# ecd5_target_db register map
Vendor: Texas Instruments
Peripheral module from a debugger description file (folder iva2_arp32).
Address unit: 16 bits
Registers are 32-bit, access per field, reset 0x0 unless marked. A register's access mark holds for its fields unless they carry their own. Offsets are as the file gives them; lines under a group give offsets from that group; [hi:lo] are bit positions; {n}, {i} and the like mark numbered series; 'fields as' and 'values as' point back to an identical list; <NAME> marks a mode.

## DSS (part 1 of 5) — ipxact12_to_ccs_generated
0x00 __ALL___PID ro — ECD5 PID
0x00 __ALL___SL2_BUF_ADDR_SLICEINFO — sliceInfo SL2 Buffer Base Address
  [21:0] ADDR rw — Base Address of sliceInfo in SL2 (128 bit aligned); bits[3:0] hardwired to 0
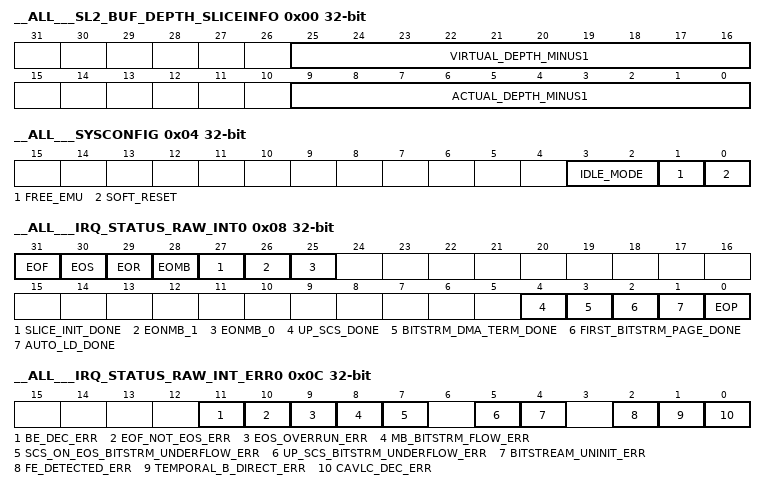
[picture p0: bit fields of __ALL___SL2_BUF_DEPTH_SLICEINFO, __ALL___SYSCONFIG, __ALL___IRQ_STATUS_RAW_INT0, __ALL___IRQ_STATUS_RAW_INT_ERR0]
0x00 __ALL___SL2_BUF_DEPTH_SLICEINFO — Buffer Control Parameters for sliceInfo Buffer Note : This register is used by the FE for handling the SL2BC to the BE and ROP as well as for describing the input sliceInfo buffer to FE.
  [25:16] VIRTUAL_DEPTH_MINUS1 rw — BC Virtual Depth
  [9:0] ACTUAL_DEPTH_MINUS1 rw — BC Actual Depth
0x04 __ALL___SYSCONFIG — SYSCONFIG
  [3:2] IDLE_MODE rw, [1] FREE_EMU rw, [0] SOFT_RESET rw
0x04 __ALL___SL2_BUF_ADDR_BITSTRM — Bitstream SL2 Buffer Base Address
  [21:0] ADDR rw — Base address of bit stream buffer in SL2 (128 bit aligned); bits[3:0] hardwired to 0
0x04 __ALL___SL2_BUF_START_PTR_SLICEINFO — Buffer Control Pointers for sliceInfo Buffer (to BE + ROP) Note : This register is used by the FE for handling the SL2BC to the BE and ROP as well as for describing the input sliceInfo buffer to FE.
  [9:0] START_PTR rw — BC Start Value for Write Pointer. Also used as the start value for reading the sliceInfo buffer by the FE.
0x08 __ALL___IRQ_STATUS_RAW_INT0 — Raw status of sources for interrupt INT0. Raw status is set even if the interrupt is not enabled; Write 1 to set the raw status (mostly for debug) The following is the behavior for read/write into each of the individual fields : Write 0: No action Write 1: Set event (for debug) Read 0: No event pending Read 1: Event pending
  [31] EOF rw — End of Frame Status.
  [30] EOS rw — End of Slice Status.
  [29] EOR rw — End of Row Status.
  [28] EOMB rw — End of Macroblock Status.
  [27] SLICE_INIT_DONE rw — Slice init done status
  [26] EONMB_1 rw — End of N Macroblock (i.e. counter 1 expired) Status.
  [25] EONMB_0 rw — End of N Macroblock (i.e. counter 0 expired) Status.
  [4] UP_SCS_DONE rw — Unit processing startcode search done. This bit is valid only in CAVLC decode.
  [3] BITSTRM_DMA_TERM_DONE rw — Bitstream DMA termination completed status. This bit is valid only in CAVLC decode.
  [2] FIRST_BITSTRM_PAGE_DONE rw — DMA of first page of bitstream fetch from DDR to SL2 completed in decode status. This bit is valid only in CAVLC decode.
  [1] AUTO_LD_DONE rw — Auto Load Done Status.
  [0] EOP rw — End of Pipe Status.
{0x8+4i} __ALL___SL2_BUF_ADDR_BIN{i} (i=0..3) — Bin Stream {i} SL2 Buffer base address
  [21:0] ADDR rw — Base Address of Bin stream {i} in SL2 (128 bit aligned); bits[3:0] hardwired to 0
0x08 __ALL___SL2_BUF_PTR_INC_SLICEINFO reset 0x1 — Buffer Control Pointer Increment Parameters for sliceInfo buffer (to BE + ROP) Note : This register is used by the FE for handling the SL2BC to the BE and ROP as well as for describing the input sliceInfo buffer to FE.
  [9:0] PTR_INC rw — BC Increment value for Write pointer. Also used as the increment value for the read pointer for reading sliceInfo buffer by FE.
0x0C __ALL___IRQ_STATUS_RAW_INT_ERR0 — Raw status of sources for interrupt INT_ERR0 Raw status is set even if the interrupt is not enabled; Write 1 to set the raw status (mostly for debug) The following is the behavior for read/write into each of the individual fields : Write 0: No action Write 1: Set event (for debug) Read 0: No event pending Read 1: Event pending
  [11] BE_DEC_ERR rw — BE Decoder Error. Tthe exact source of error is reflected in BE_STATUS.BE_CORE_ERR_STATUS
  [10] EOF_NOT_EOS_ERR rw — End of frame is not end of slice error. This bit is valid only in CAVLC decode. This error status bit is set if the corresponding error enable bit (BE_FUNC.CAVLC_CFG.EOF_NOT_EOS_ERROR_ENABLE) is set and the following condition is true : - End of slice is not detected in the CAVLC bitstream, but all MBs in the picture have been decoded.
  [9] EOS_OVERRUN_ERR rw — End of slice overrun error. This bit is valid only in CAVLC decode. This error status bit is set, if during MB decoding, bit pointer overruns the position of end of slice. Byte stream format : If the bit pointer overruns the start code of the next slice, this status bit is set. NALU or fragmented NALU format : If the bit counter reaches the programmed size (BITSTRMx_CTRL.SBC_NALU_CFG.SIZE) of NALU and slice data decode is not completed, this status bit is set
  [8] MB_BITSTRM_FLOW_ERR rw — During decode, underflow in bitstream during MB decode error. This bit is valid only in CAVLC decode or encode. This error status bit is set when the ECD5 reached the end of the provided bitstream during macroblock decode. During encode, overflow in bitstream during MB encode error. This error status bit is set when the ECD5 reached the end of the provided DDR buffer during macroblock encode.
  [7] SCS_ON_EOS_BITSTRM_UNDERFLOW_ERR rw — Underflow in bitstream during startcode search after EOS error. This bit is valid only in CAVLC decode. This error status bit is set when the ECD5 does not detect startcode even after decoding all the bitstream data provided, while doing a startcode search after EOS.
  [5] UP_SCS_BITSTRM_UNDERFLOW_ERR rw — Underflow in bitstream during startcode search unit processing This bit is valid only in CAVLC decode. This error status bit is set when the ECD5 does not detect startcode even after decoding all the bitstream data provided, while doing startcode search unit processing.
  [4] BITSTREAM_UNINIT_ERR rw — Bitstream descriptors were not programmed when bit stream DMA was initialized, error. This bit is valid only in CAVLC decode. This error status bit is set when bit-stream DMA is triggered (internally by the HW, or externally through SW programmation) but the bit-stream descriptors have not been programmed before this happens.
  [2] FE_DETECTED_ERR rw — BE error due to error detected in FE. This bit is valid only in CABAC decode , in both frame decoupled and non-frame-decoupled modes. This error status bit is set when the ECD5 detects an error in the BE, due to an error indication from the FE. The error indication from the FE is obtained as follows : - in frame decoupled mode, when the BE reaches an MB programmed as an error MB in BE_ERROR_MB_CFG - in non-frame decoupled mode, when the BE reaches an MB indicated as an error MB through internal signalling from the BE
  [1] TEMPORAL_B_DIRECT_ERR rw — Temporal B Direct Detected Error. This bit is valid only in CAVLC decode. This error status bit is set if Temporal B Direct decode is disabled (by setting BE_FUNC.CAVLC_CFG.TEMPORAL_B_DIRECT_ERROR_ENABLE to 1) and a Temporal B Direct MB is detected in the decoded (CAVLC) bit stream
  [0] CAVLC_DEC_ERR rw — CAVLC Decoder Error. This bit is valid only in CAVLC decode. Tthe exact source of error is reflected in BE_STAT.CAVLC_ERR_STATUS
0x0C __ALL___SL2_BUF_DEPTH_MB — Buffer Control Parameters for MB decoupling between FE and BE Note : Valid only in N MB decoupled mode
  [9:0] ACTUAL_DEPTH_MINUS1 rw — BC Actual Depth
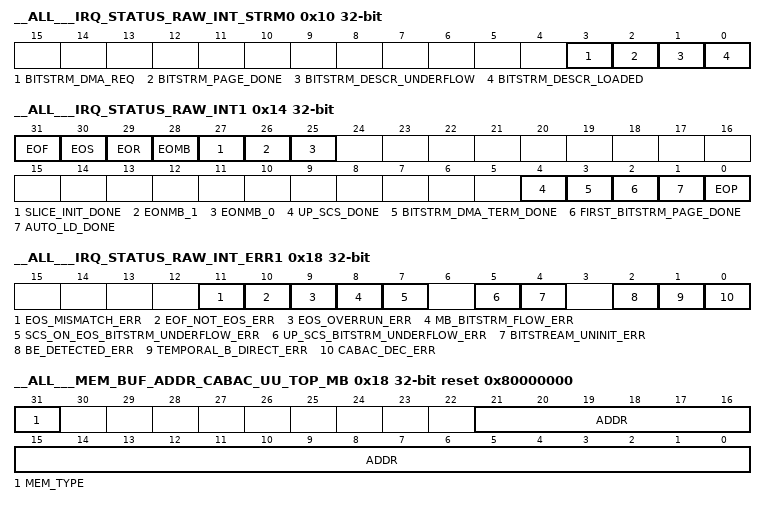
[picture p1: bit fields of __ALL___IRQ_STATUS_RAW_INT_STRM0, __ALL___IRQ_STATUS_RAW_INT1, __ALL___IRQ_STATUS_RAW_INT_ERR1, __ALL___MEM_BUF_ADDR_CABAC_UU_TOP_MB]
0x10 __ALL___IRQ_STATUS_RAW_INT_STRM0 — Raw status of sources for interrupt INT_STRM0 Raw status is set even if the interrupt is not enabled; Write 1 to set the raw status (mostly for debug) The following is the behavior for read/write into each of the individual fields : Write 0: No action Write 1: Set event (for debug) Read 0: No event pending Read 1: Event pending
  [3] BITSTRM_DMA_REQ rw — DMA request status. This bit is valid only in SW interactive mode of bitstream DMA - if "1" indicates that a request for DMA of 1 page of bitstream data is pending
  [2] BITSTRM_PAGE_DONE rw — Status bit indicating completion of - in decode, DMA of 1 page of bitstream fetch from DDR to SL2 - in encode, DMA of 1 page of bitstream write from SL2 to DDR
  [1] BITSTRM_DESCR_UNDERFLOW rw — DDR or SL2 bitstream data descriptor underflow status. In regular mode of bitstream DRM operation, this bit is set when contents of DDR_BITSTRM_INC_VALID_PAGES_SHADOW in the BITSTRM0_CTRL register set transitions to 0, and the corresponding non-shadow register - DDR_BITSTRM_INC_VALID_PAGES - has not yet been programmed with new value. In DMSP mode of bitstream DRM operation, this bit is set when contents of SL2_BITSTRM_INC_VALID_PAGES_SHADOW in the BITSTRM0_CTRL register set transitions to 0, and the corresponding non-shadow register - SL2_BITSTRM_INC_VALID_PAGES - has not yet been programmed with new value.
  [0] BITSTRM_DESCR_LOADED rw — DDR or SL2 bitstream data descriptor loaded status. In regular mode of bitstream DRM operation, this bit is set when contents of DDR_BITSTRM_INC_VALID_PAGES in the BITSTRM0_CTRL register set are copied into the corresponding shadow register, when the DDR_BITSTRM_INC_VALID_PAGES_SHADOW register contents transition to 0 Note that this bit is not set when the shadow registers are updated for the first time (i.e. when DDR_BITSTRM_INC_VALID_PAGES is written for the first time (and the corresponding shadow register is empty) In DMSP mode of bitstream DRM operation, this bit is set when contents of SL2_BITSTRM_INC_VALID_PAGES in the BITSTRM0_CTRL register set are copied into the corresponding shadow register, when the SL2_BITSTRM_INC_VALID_PAGES_SHADOW register contents transition to 0 Note that this bit is not set when the shadow registers are updated for the first time (i.e. when SL2_BITSTRM_INC_VALID_PAGES is written for the first time (and the corresponding shadow register is empty)
0x14 __ALL___IRQ_STATUS_RAW_INT1 — Raw status of sources for interrupt INT1; Raw status is set even if the interrupt is not enabled; Write 1 to set the raw status (mostly for debug) The following is the behavior for read/write into each of the individual fields : Write 0: No action Write 1: Set event (for debug) Read 0: No event pending Read 1: Event pending
  [31] EOF rw — End of Frame Status
  [30] EOS rw — End of Slice Status
  [29] EOR rw — End of Row Status
  [28] EOMB rw — End of Macroblock Status
  [27] SLICE_INIT_DONE rw — Slice init done status
  [26] EONMB_1 rw — End of N Macroblock (i.e. counter 1 expired) Status.
  [25] EONMB_0 rw — End of N Macroblock (i.e. counter 0 expired) Status.
  [4] UP_SCS_DONE rw — Unit processing startcode search done. This bit is valid only in CABAC decode.
  [3] BITSTRM_DMA_TERM_DONE rw — Bitstream DMA termination completed status. This bit is valid only in CABAC decode.
  [2] FIRST_BITSTRM_PAGE_DONE rw — DMA of first page of bitstream fetch from DDR to SL2 completed in decode status. This bit is valid only in CABAC decode.
  [1] AUTO_LD_DONE rw — Auto Load Done Status
  [0] EOP rw — End of Pipe Status
0x18 __ALL___IRQ_STATUS_RAW_INT_ERR1 — Raw status of sources for interrupt INT_ERR1 Raw status is set even if the interrupt is not enabled; Write 1 to set the raw status (mostly for debug) The following is the behavior for read/write into each of the individual fields : Write 0: No action Write 1: Set event (for debug) Read 0: No event pending Read 1: Event pending
  [11] EOS_MISMATCH_ERR rw — End of slice mismatch error. This bit is valid only in CABAC decode. This error status bit is set if the corresponding error enable bit (FE_FUNC.CABAC_CFG.EOS_MISMATCH_ERROR_ENABLE) is set and one of the following conditions is true : * There is no more data in the CABAC bitstream (more_rbsp_data() is false), but end of slice is not detected in the bitstream * End of slice is detected in the CABAC bitstream, but there is still more data to be decoded in the slice (more_rbsp_data() is true)
  [10] EOF_NOT_EOS_ERR rw — End of frame is not end of slice error. This bit is valid only in CABAC decode. This error status bit is set if the corresponding error enable bit (FE_FUNC.CABAC_CFG.EOF_NOT_EOS_ERROR_ENABLE) is set and if the following conditions is true : - End of slice is not detected in the CABAC bitstream, but all MBs in the picture have been decoded.
  [9] EOS_OVERRUN_ERR rw — End of slice overrun error. This bit is valid only in CABAC decode. This error status bit is set, if during MB decoding, bit pointer overruns the position of end of slice. Byte stream format : If the bit pointer overruns the start code of the next slice, this status bit is set. NALU or fragmented NALU format : If the bit counter reaches the programmed size (BITSTRMx_CTRL.SBC_NALU_CFG.SIZE) of NALU and slice data decode is not completed, this status bit is set
  [8] MB_BITSTRM_FLOW_ERR rw — During decode, underflow in bitstream during MB decode error. This bit is valid only in CABAC decode. This error status bit is set when the ECD5 reached the end of the provided bitstream during macroblock decode.
  [7] SCS_ON_EOS_BITSTRM_UNDERFLOW_ERR rw — Underflow in bitstream during startcode search after EOS error. This bit is valid only in CABAC decode. This error status bit is set when the ECD5 does not detect startcode even after decoding all the bitstream data provided, while doing a startcode search after EOS.
  [5] UP_SCS_BITSTRM_UNDERFLOW_ERR rw — Underflow in bitstream during startcode search unit processing This error status bit is set when the ECD5 does not detect startcode even after decoding all the bitstream data provided, while doing startcode search unit processing.
  [4] BITSTREAM_UNINIT_ERR rw — Bitstream descriptors were not programmed when bit stream DMA was initialized, error. This bit is valid only in CABAC decode. This error status bit is set when bit-stream DMA is triggered (internally by the HW, or externally through SW programmation) but the bit-stream descriptors have not been programmed before this happens.
  [2] BE_DETECTED_ERR rw — FE error due to error detected in BE. This bit is valid only in CABAC decode in non-frame decoupled mode, or in CAVLC decode. This error status bit is set when the ECD5 detects an error in the FE, due to an error indication from the BE through internal signalling.
  [1] TEMPORAL_B_DIRECT_ERR rw — Temporal B Direct Detected Error. This error status bit is set if Temporal B Direct decode is disabled (by setting FE_FUNC.CABAC_CFG.TEMPORAL_B_DIRECT_ERROR_ENABLE to 1) and a Temporal B Direct MB is detected in the decoded (CABAC) bit stream
  [0] CABAC_DEC_ERR rw — CABAC Decoder Error; the exact source of error is reflected in FE_STATUS.CABAC_ERR_STATUS
0x18 __ALL___MEM_BUF_ADDR_CABAC_UU_TOP_MB reset 0x80000000 — Upper Top MB Buffer Base Address for CABAC neighouring MB data in internal memory or SL2
  [31] MEM_TYPE rw — Specifies whether buffer is in SL2 or internal memory 0 : SL2, 1 : Internal memory
  [21:0] ADDR rw — Base Address for Upper MB Row, Top MB in the Pair If MEM_TYPE == 0, address in SL2 (128 bit aligned) specified; bits[3:0] hardwired to 0 If MEM_TYPE == 1, address in internal memory (128 bit aligned) specified;bits[3:0] hardwired to 0; bits [22:15] unused.
{0x18+8i} __ALL___SL2_BUF_DEPTH_BIN{i} (i=0..3) — Buffer Control Parameters for bin stream {i} Note : Valid only in N MB decoupled mode
  [15:0] ACTUAL_DEPTH_MINUS1 rw — BC Actual Depth
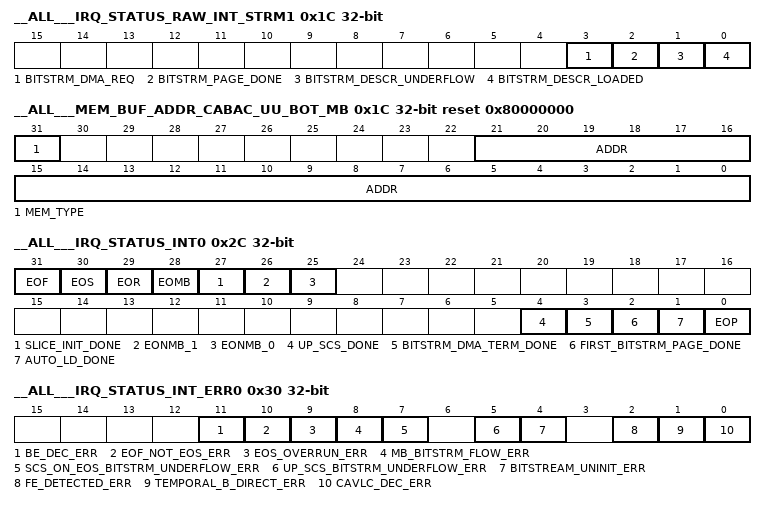
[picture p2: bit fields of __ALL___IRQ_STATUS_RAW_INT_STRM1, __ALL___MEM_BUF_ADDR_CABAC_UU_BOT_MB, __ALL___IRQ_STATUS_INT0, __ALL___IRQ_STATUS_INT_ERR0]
0x1C __ALL___IRQ_STATUS_RAW_INT_STRM1 — Raw status of sources for interrupt INT_STRM1 Raw status is set even if the interrupt is not enabled; Write 1 to set the raw status (mostly for debug) The following is the behavior for read/write into each of the individual fields : Write 0: No action Write 1: Set event (for debug) Read 0: No event pending Read 1: Event pending
  [3] BITSTRM_DMA_REQ rw — DMA request status. This bit is valid only in SW interactive mode of bitstream DMA - if "1" indicates that a request for DMA of 1 page of bitstream data is pending
  [2] BITSTRM_PAGE_DONE rw — Status bit indicating completion of - in decode, DMA of 1 page of bitstream fetch from DDR to SL2 - in encode, DMA of 1 page of bitstream write from SL2 to DDR
  [1] BITSTRM_DESCR_UNDERFLOW rw — DDR or SL2 bitstream data descriptor underflow status. In regular mode of bitstream DRM operation, this bit is set when contents of DDR_BITSTRM_INC_VALID_PAGES_SHADOW in the BITSTRM1_CTRL register set transitions to 0, and the corresponding non-shadow register - DDR_BITSTRM_INC_VALID_PAGES - has not yet been programmed with new value. In DMSP mode of bitstream DRM operation, this bit is set when contents of SL2_BITSTRM_INC_VALID_PAGES_SHADOW in the BITSTRM1_CTRL register set transitions to 0, and the corresponding non-shadow register - SL2_BITSTRM_INC_VALID_PAGES - has not yet been programmed with new value.
  [0] BITSTRM_DESCR_LOADED rw — DDR or SL2 bitstream data descriptor loaded status. In regular mode of bitstream DRM operation, this bit is set when contents of DDR_BITSTRM_INC_VALID_PAGES in the BITSTRM1_CTRL register set are copied into the corresponding shadow register, when the DDR_BITSTRM_INC_VALID_PAGES_SHADOW register contents transition to 0 Note that this bit is not set when the shadow registers are updated for the first time (i.e. when DDR_BITSTRM_INC_VALID_PAGES is written for the first time (and the corresponding shadow register is empty) In DMSP mode of bitstream DRM operation, this bit is set when contents of SL2_BITSTRM_INC_VALID_PAGES in the BITSTRM1_CTRL register set are copied into the corresponding shadow register, when the SL2_BITSTRM_INC_VALID_PAGES_SHADOW register contents transition to 0 Note that this bit is not set when the shadow registers are updated for the first time (i.e. when SL2_BITSTRM_INC_VALID_PAGES is written for the first time (and the corresponding shadow register is empty)
0x1C __ALL___MEM_BUF_ADDR_CABAC_UU_BOT_MB reset 0x80000000 — Upper Top MB Buffer Base Address for CABAC neighouring MB data in internal memory or SL2
  [31] MEM_TYPE rw — Specifies whether buffer is in SL2 or internal memory 0 : SL2, 1 : Internal memory
  [21:0] ADDR rw — Base Address for Upper MB Row, Bottom MB in the Pair If MEM_TYPE == 0, address in SL2 (128 bit aligned) specified; bits[3:0] hardwired to 0 If MEM_TYPE == 1, address in internal memory (128 bit aligned) specified;bits[3:0] hardwired to 0; bits [22:15] unused.
{0x1C+8i} __ALL___SL2_BUF_START_PTR_BIN{i} rw (i=0..3) — Buffer Control Pointers for bin stream {i} Note : Valid only in N MB decoupled mode
  [15:0] WRITE_START_PTR — BC Start Value for Write Pointer
0x2C __ALL___IRQ_STATUS_INT0 — Status of enabled sources for interrupt INT0. The individual status bits are not set, unless the source is enabled (by setting corresponding bit in IRQ_ENABLE_SET register) Write "1" to specific bit in this register to clear the status after interrupt has been serviced. Note : Writing "1" clears the "raw" status as well Note : Writing "1" generates internal EOI. The interrupt line is pulsed again, if any of the interrupt sources are still active (any of the status bits are "1") after the write of "1". The following is the behavior for read/write into each of the individual fields : Write 0: No action Write 1: Clear (raw) event - clears the corresponding bit in this register as well as the "raw" status bit in the IRQ_STATUS_RAW register Read 0: No enabled event pending Read 1: Event pending
  [31] EOF rw — End of Frame Status
  [30] EOS rw — End of Slice Status
  [29] EOR rw — End of Row Status
  [28] EOMB rw — End of Macroblock Status
  [27] SLICE_INIT_DONE rw — Slice init done status
  [26] EONMB_1 rw — End of N Macroblock (i.e. counter 1 expired) Status.
  [25] EONMB_0 rw — End of N Macroblock (i.e. counter 0 expired) Status.
  [4] UP_SCS_DONE rw — Unit processing startcode search done. This bit is valid only in CAVLC decode.
  [3] BITSTRM_DMA_TERM_DONE rw — Bitstream DMA termination completed status. This bit is valid only in CAVLC decode.
  [2] FIRST_BITSTRM_PAGE_DONE rw — DMA of first page of bitstream fetch from DDR to SL2 completed in decode status. This bit is valid only in CAVLC decode.
  [1] AUTO_LD_DONE rw — Auto Load Done Status
  [0] EOP rw — End of Pipe Status
0x30 __ALL___IRQ_STATUS_INT_ERR0 — Status of enabled sources for interrupt INT_ERR0. The individual status bits are not set, unless the source is enabled (by setting corresponding bit in IRQ_ENABLE_SET register) Write "1" to specific bit in this register to clear the status after interrupt has been serviced. Note : Writing "1" clears the "raw" status as well Note : Writing "1" generates internal EOI. The interrupt line is pulsed again, if any of the interrupt sources are still active (any of the status bits are "1") after the write of "1". The following is the behavior for read/write into each of the individual fields : Write 0: No action Write 1: Clear (raw) event - clears the corresponding bit in this register as well as the "raw" status bit in the IRQ_STATUS_RAW register Read 0: No enabled event pending Read 1: Event pending
  [11] BE_DEC_ERR rw — BE Decoder Error. Tthe exact source of error is reflected in BE_STATUS.BE_CORE_ERR_STATUS
  [10] EOF_NOT_EOS_ERR rw — End of frame is not end of slice error. This bit is valid only in CAVLC decode. This error status bit is set if the corresponding error enable bit (BE_FUNC.CAVLC_CFG.EOF_NOT_EOS_ERROR_ENABLE) is set and the following condition is true : - End of slice is not detected in the CAVLC bitstream, but all MBs in the picture have been decoded.
  [9] EOS_OVERRUN_ERR rw — End of slice overrun error. This bit is valid only in CAVLC decode. This error status bit is set, if during MB decoding, bit pointer overruns the position of end of slice. Byte stream format : If the bit pointer overruns the start code of the next slice, this status bit is set. NALU or fragmented NALU format : If the bit counter reaches the programmed size (BITSTRMx_CTRL.SBC_NALU_CFG.SIZE) of NALU and slice data decode is not completed, this status bit is set
  [8] MB_BITSTRM_FLOW_ERR rw — During decode, underflow in bitstream during MB decode error. This bit is valid only in CAVLC decode or encode. This error status bit is set when the ECD5 reached the end of the provided bitstream during macroblock decode. During encode, overflow in bitstream during MB encode error. This error status bit is set when the ECD5 reached the end of the provided DDR buffer during macroblock encode.
  [7] SCS_ON_EOS_BITSTRM_UNDERFLOW_ERR rw — Underflow in bitstream during startcode search after EOS error. This bit is valid only in CAVLC decode. This error status bit is set when the ECD5 does not detect startcode even after decoding all the bitstream data provided, while doing a startcode search after EOS.
  [5] UP_SCS_BITSTRM_UNDERFLOW_ERR rw — Underflow in bitstream during startcode search unit processing. This bit is valid only in CAVLC decode. This error status bit is set when the ECD5 does not detect startcode even after decoding all the bitstream data provided, while doing startcode search unit processing.
  [4] BITSTREAM_UNINIT_ERR rw — Bitstream descriptors were not programmed when bit stream DMA was initialized, error. This bit is valid only in CAVLC decode. This error status bit is set when bit-stream DMA is triggered (internally by the HW, or externally through SW programmation) but the bit-stream descriptors have not been programmed before this happens.
  [2] FE_DETECTED_ERR rw — BE error due to error detected in FE. This bit is valid only in CABAC decode , in both frame decoupled and non-frame-decoupled modes. This error status bit is set when the ECD5 detects an error in the BE, due to an error indication from the FE. The error indication from the FE is obtained as follows : - in frame decoupled mode, when the BE reaches an MB programmed as an error MB in ECD5_BE_ERROR_MB_CFG - in non-frame decoupled mode, when the BE reaches an MB indicated as an error MB through internal signalling from the BE (TBD)
  [1] TEMPORAL_B_DIRECT_ERR rw — Temporal B Direct Detected Error. This bit is valid only in CAVLC decode. This error status bit is set if Temporal B Direct decode is disabled (by setting BE_FUNC.CAVLC_CFG.TEMPORAL_B_DIRECT_ERROR_ENABLE to 1) and a Temporal B Direct MB is detected in the decoded (CAVLC) bit stream
  [0] CAVLC_DEC_ERR rw — CAVLC Decoder Error. This bit is valid only in CAVLC decode. Tthe exact source of error is reflected in BE_STAT.CAVLC_ERR_STATUS
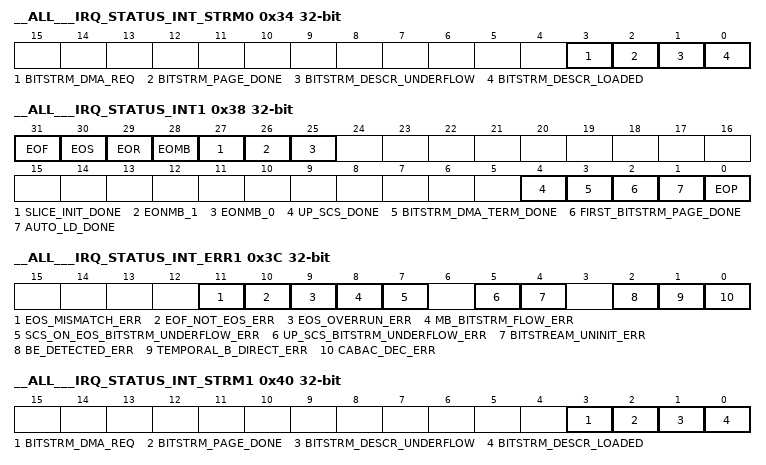
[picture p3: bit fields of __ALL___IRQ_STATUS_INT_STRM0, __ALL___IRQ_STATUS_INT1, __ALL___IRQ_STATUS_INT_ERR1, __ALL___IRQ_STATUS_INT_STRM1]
0x34 __ALL___IRQ_STATUS_INT_STRM0 — Status of enabled sources for interrupt INT_STRM0. The individual status bits are not set, unless the source is enabled (by setting corresponding bit in IRQ_ENABLE_SET register) Write "1" to specific bit in this register to clear the status after interrupt has been serviced. Note : Writing "1" clears the "raw" status as well Note : Writing "1" generates internal EOI. The interrupt line is pulsed again, if any of the interrupt sources are still active (any of the status bits are "1") after the write of "1". The following is the behavior for read/write into each of the individual fields : Write 0: No action Write 1: Clear (raw) event - clears the corresponding bit in this register as well as the "raw" status bit in the IRQ_STATUS_RAW register Read 0: No enabled event pending Read 1: Event pending
  [3] BITSTRM_DMA_REQ rw — DMA request status. This bit is valid only in SW interactive mode of bitstream DMA - if "1" indicates that a request for DMA of 1 page of bitstream data is pending Clearing this bit signals completion of DMA of the pag eto the H/W
  [2] BITSTRM_PAGE_DONE rw — Status bit indicating completion of - in decode, DMA of 1 page of bitstream fetch from DDR to SL2 - in encode, DMA of 1 page of bitstream write from SL2 to DDR
  [1] BITSTRM_DESCR_UNDERFLOW rw — DDR or SL2 bitstream data descriptor underflow status. In regular mode of bitstream DRM operation, this bit is set when contents of DDR_BITSTRM_INC_VALID_PAGES_SHADOW in the BITSTRM0_CTRL register set transitions to 0, and the corresponding non-shadow register - DDR_BITSTRM_INC_VALID_PAGES - has not yet been programmed with new value. In DMSP mode of bitstream DRM operation, this bit is set when contents of SL2_BITSTRM_INC_VALID_PAGES_SHADOW in the BITSTRM0_CTRL register set transitions to 0, and the corresponding non-shadow register - SL2_BITSTRM_INC_VALID_PAGES - has not yet been programmed with new value.
  [0] BITSTRM_DESCR_LOADED rw — DDR or SL2 bitstream data descriptor loaded status. In regular mode of bitstream DRM operation, this bit is set when contents of DDR_BITSTRM_INC_VALID_PAGES in the BITSTRM0_CTRL register set are copied into the corresponding shadow register, when the DDR_BITSTRM_INC_VALID_PAGES_SHADOW register contents transition to 0 Note that this bit is not set when the shadow registers are updated for the first time (i.e. when DDR_BITSTRM_INC_VALID_PAGES is written for the first time (and the corresponding shadow register is empty) In DMSP mode of bitstream DRM operation, this bit is set when contents of SL2_BITSTRM_INC_VALID_PAGES in the BITSTRM0_CTRL register set are copied into the corresponding shadow register, when the SL2_BITSTRM_INC_VALID_PAGES_SHADOW register contents transition to 0 Note that this bit is not set when the shadow registers are updated for the first time (i.e. when SL2_BITSTRM_INC_VALID_PAGES is written for the first time (and the corresponding shadow register is empty)
0x38 __ALL___IRQ_STATUS_INT1 — Status of enabled sources for interrupt INT1. The individual status bits are not set, unless the source is enabled (by setting corresponding bit in IRQ_ENABLE_SET register) Write "1" to specific bit in this register to clear the status after interrupt has been serviced. Note : Writing "1" clears the "raw" status as well Note : Writing "1" generates internal EOI. The interrupt line is pulsed again, if any of the interrupt sources are still active (any of the status bits are "1") after the write of "1". The following is the behavior for read/write into each of the individual fields : Write 0: No action Write 1: Clear (raw) event - clears the corresponding bit in this register as well as the "raw" status bit in the IRQ_STATUS_RAW register Read 0: No enabled event pending Read 1: Event pending
  fields as __ALL___IRQ_STATUS_RAW_INT1
0x3C __ALL___IRQ_STATUS_INT_ERR1 — Status of enabled sources for interrupt INT_ERR1. The individual status bits are not set, unless the source is enabled (by setting corresponding bit in IRQ_ENABLE_SET register) Write "1" to specific bit in this register to clear the status after interrupt has been serviced. Note : Writing "1" clears the "raw" status as well Note : Writing "1" generates internal EOI. The interrupt line is pulsed again, if any of the interrupt sources are still active (any of the status bits are "1") after the write of "1". The following is the behavior for read/write into each of the individual fields : Write 0: No action Write 1: Clear (raw) event - clears the corresponding bit in this register as well as the "raw" status bit in the IRQ_STATUS_RAW register Read 0: No enabled event pending Read 1: Event pending
  [11] EOS_MISMATCH_ERR rw — End of slice mismatch error. This bit is valid only in CABAC decode. This error status bit is set if the corresponding error enable bit (FE_FUNC.CABAC_CFG.EOS_MISMATCH_ERROR_ENABLE) is set and one of the following conditions is true : * There is no more data in the CABAC bitstream (more_rbsp_data() is false), but end of slice is not detected in the bitstream * End of slice is detected in the CABAC bitstream, but there is still more data to be decoded in the slice (more_rbsp_data() is true)
  [10] EOF_NOT_EOS_ERR rw — End of frame is not end of slice error. This bit is valid only in CABAC decode. This error status bit is set if the corresponding error enable bit (FE_FUNC.CABAC_CFG.EOF_NOT_EOS_ERROR_ENABLE) is set and if the following conditions is true : - End of slice is not detected in the CABAC bitstream, but all MBs in the picture have been decoded.
  [9] EOS_OVERRUN_ERR rw — End of frame is not end of slice error. This bit is valid only in CABAC decode. This error status bit is set if the corresponding error enable bit (FE_FUNC.CABAC_CFG.EOF_NOT_EOS_ERROR_ENABLE) is set and if the following conditions is true : - End of slice is not detected in the CABAC bitstream, but all MBs in the picture have been decoded.
  [8] MB_BITSTRM_FLOW_ERR rw — During decode, underflow in bitstream during MB decode error. This bit is valid only in CABAC decode. This error status bit is set when the ECD5 reached the end of the provided bitstream during macroblock decode.
  [7] SCS_ON_EOS_BITSTRM_UNDERFLOW_ERR rw — Underflow in bitstream during startcode search after EOS error. This bit is valid only in CABAC decode. This error status bit is set when the ECD5 does not detect startcode even after decoding all the bitstream data provided, while doing a startcode search after EOS.
  [5] UP_SCS_BITSTRM_UNDERFLOW_ERR rw — Underflow in bitstream during startcode search unit processing. This error status bit is set when the ECD5 does not detect startcode even after decoding all the bitstream data provided, while doing startcode search unit processing.
  [4] BITSTREAM_UNINIT_ERR rw — Bitstream descriptors were not programmed when bit stream DMA was initialized, error. This bit is valid only in CABAC decode. This error status bit is set when bit-stream DMA is triggered (internally by the HW, or externally through SW programmation) but the bit-stream descriptors have not been programmed before this happens.
  [2] BE_DETECTED_ERR rw — FE error due to error detected in BE. This bit is valid only in CABAC decode in non-frame decoupled mode, or in CAVLC decode. This error status bit is set when the ECD5 detects an error in the FE, due to an error indication from the BE through internal signalling.
  [1] TEMPORAL_B_DIRECT_ERR rw — Temporal B Direct Detected Error. This error status bit is set if Temporal B Direct decode is disabled (by setting FE_FUNC.CABAC_CFG.TEMPORAL_B_DIRECT_ERROR_ENABLE to 1) and a Temporal B Direct MB is detected in the decoded (CABAC) bit stream
  [0] CABAC_DEC_ERR rw — CABAC Decoder Error; the exact source of error is reflected in FE_STATUS.CABAC_ERR_STATUS
0x40 __ALL___IRQ_STATUS_INT_STRM1 — Status of enabled sources for interrupt INT_STRM1. The individual status bits are not set, unless the source is enabled (by setting corresponding bit in IRQ_ENABLE_SET register) Write "1" to specific bit in this register to clear the status after interrupt has been serviced. Note : Writing "1" clears the "raw" status as well Note : Writing "1" generates internal EOI. The interrupt line is pulsed again, if any of the interrupt sources are still active (any of the status bits are "1") after the write of "1". The following is the behavior for read/write into each of the individual fields : Write 0: No action Write 1: Clear (raw) event - clears the corresponding bit in this register as well as the "raw" status bit in the IRQ_STATUS_RAW register Read 0: No enabled event pending Read 1: Event pending
  [3] BITSTRM_DMA_REQ rw — DMA request status. This bit is valid only in SW interactive mode of bitstream DMA - if "1" indicates that a request for DMA of 1 page of bitstream data is pending Clearing this bit signals completion of DMA of the pag eto the H/W
  [2] BITSTRM_PAGE_DONE rw — Status bit indicating completion of - in decode, DMA of 1 page of bitstream fetch from DDR to SL2 - in encode, DMA of 1 page of bitstream write from SL2 to DDR
  [1] BITSTRM_DESCR_UNDERFLOW rw — DDR or SL2 bitstream data descriptor underflow status. In regular mode of bitstream DRM operation, this bit is set when contents of DDR_BITSTRM_INC_VALID_PAGES_SHADOW in the BITSTRM1_CTRL register set transitions to 0, and the corresponding non-shadow register - DDR_BITSTRM_INC_VALID_PAGES - has not yet been programmed with new value. In DMSP mode of bitstream DRM operation, this bit is set when contents of SL2_BITSTRM_INC_VALID_PAGES_SHADOW in the BITSTRM1_CTRL register set transitions to 0, and the corresponding non-shadow register - SL2_BITSTRM_INC_VALID_PAGES - has not yet been programmed with new value.
  [0] BITSTRM_DESCR_LOADED rw — DDR or SL2 bitstream data descriptor loaded status. In regular mode of bitstream DRM operation, this bit is set when contents of DDR_BITSTRM_INC_VALID_PAGES in the BITSTRM1_CTRL register set are copied into the corresponding shadow register, when the DDR_BITSTRM_INC_VALID_PAGES_SHADOW register contents transition to 0 Note that this bit is not set when the shadow registers are updated for the first time (i.e. when DDR_BITSTRM_INC_VALID_PAGES is written for the first time (and the corresponding shadow register is empty) In DMSP mode of bitstream DRM operation, this bit is set when contents of SL2_BITSTRM_INC_VALID_PAGES in the BITSTRM1_CTRL register set are copied into the corresponding shadow register, when the SL2_BITSTRM_INC_VALID_PAGES_SHADOW register contents transition to 0 Note that this bit is not set when the shadow registers are updated for the first time (i.e. when SL2_BITSTRM_INC_VALID_PAGES is written for the first time (and the corresponding shadow register is empty)
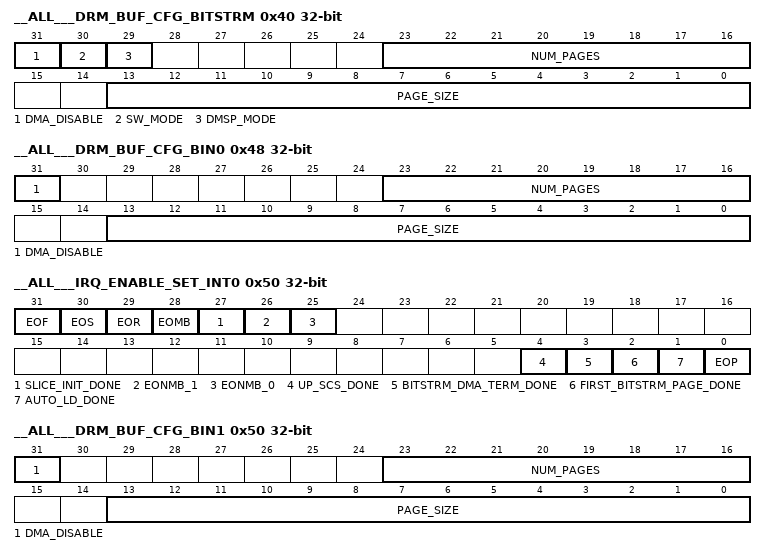
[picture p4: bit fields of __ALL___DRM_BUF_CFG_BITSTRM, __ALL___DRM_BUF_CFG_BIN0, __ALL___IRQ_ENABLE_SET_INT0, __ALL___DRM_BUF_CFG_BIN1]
0x40 __ALL___DRM_BUF_CFG_BITSTRM — Buffer parameters and configuration for bit stream Note : In the non-frame decoupled configuration, this register is used for DRM configuration. The corresponding registers in BE are unused
  [31] DMA_DISABLE rw — If '1', disables the triggering of VDMA. Only the SL2 buffer management is activated.
  [30] SW_MODE rw — If '1', specifies SW interactive mode of operation. In this mode, the ECD5 does not interact directly with VDMA for bitstream DMA. Instead it triggers an interrupt for requesting DMA transfer of bitstream.
  [29] DMSP_MODE rw — If '1', specifies "Direct Multi-page SL2 population" mode of operation
  [23:16] NUM_PAGES rw — Number of pages in SL2
  [13:0] PAGE_SIZE rw — Size of each page in SL2 (in bytes); bits[3:0] are ignored, so the effective size is a multiple of 16 bytes
0x44 __ALL___DRM_BUF_DMAGROUPID_BITSTRM — DMA Group ID for bit stream Note : In the non-frame decoupled configuration, this register is used for DRM configuration. The corresponding registers in BE are unused
  [5:0] ID rw — Group ID for VDMA transfer
0x48 __ALL___DRM_BUF_CFG_BIN0 — Buffer Parameters and configuration for bin stream 0 Note : Valid only in frame decoupled mode
  [31] DMA_DISABLE rw — If '1', disables the triggering of VDMA. Only the SL2 buffer management is activated.
  [23:16] NUM_PAGES rw — Number of pages in SL2
  [13:0] PAGE_SIZE rw — Size of each page in SL2 (in bytes); bits[3:0] are ignored, so the effective size is a multiple of 16 bytes Although the VDMA transfer for bin stream is deterministic, PAGE_SIZE is needed by ECD5 to know when to trigger VDMA - i.e. when the page becomes full. Since the size of each entry/write in the bin buffer is not fixed, the DMA is triggered when the total size of the wriiten data reaches PAGE_SIZE
0x4C __ALL___DRM_BUF_DMAGROUPID_BIN0 — DMA Group ID for bin stream 0 Note : Valid only in frame decoupled mode
  [5:0] ID rw — Group ID for VDMA transfer
0x50 __ALL___IRQ_ENABLE_SET_INT0 — Interrupt enable for each of the sources for interrupt INT0 Writing "1" to specific field in this register enables the corresponding source for interrupt generatation The read value reflects whether the corresponding source is enabled/disabled for interrupt generation The following is the behavior for read/write into each of the individual fields : Write 0: No action Write 1: Enable interrupt Read 0: Interrupt disabled (masked) Read 1: Interrupt enabled
  [31] EOF rw — End of Frame Interrupt enable
  [30] EOS rw — End of Slice Interrupt enable
  [29] EOR rw — End of Row Interrupt enable
  [28] EOMB rw — End of Macroblock Interrupt enable
  [27] SLICE_INIT_DONE rw — Slice init done interrupt enable
  [26] EONMB_1 rw — End of N Macroblock (i.e. counter 1 expired) interrupt enable.
  [25] EONMB_0 rw — End of N Macroblock (i.e. counter 0 expired) interrupt enable
  [4] UP_SCS_DONE rw — Unit processing startcode search interrupt enable.
  [3] BITSTRM_DMA_TERM_DONE rw — Bitstream DMA termination completed interrupt enable.
  [2] FIRST_BITSTRM_PAGE_DONE rw — First bitstream page DMA done interrupt enable
  [1] AUTO_LD_DONE rw — Auto Load Done Interrupt Enable
  [0] EOP rw — End of Pipe Interrupt enable
0x50 __ALL___DRM_BUF_CFG_BIN1 — Buffer Parameters and configuration for bin stream 1 Note : Valid only in frame decoupled mode
  fields as __ALL___DRM_BUF_CFG_BIN0
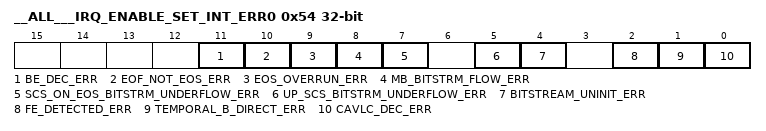
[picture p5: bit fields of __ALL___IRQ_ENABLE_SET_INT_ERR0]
0x54 __ALL___IRQ_ENABLE_SET_INT_ERR0 — Interrupt enable for each of the sources for interrupt INT_ERR0 Writing "1" to specific field in this register enables the corresponding source for interrupt generatation The read value reflects whether the corresponding source is enabled/disabled for interrupt generation The following is the behavior for read/write into each of the individual fields : Write 0: No action Write 1: Enable interrupt Read 0: Interrupt disabled (masked) Read 1: Interrupt enabled
  [11] BE_DEC_ERR rw — BE Decoder Error interrupt enable
  [10] EOF_NOT_EOS_ERR rw — End of frame is not end of slice error interrupt enable
  [9] EOS_OVERRUN_ERR rw — End of slice overrun error interrupt enable
  [8] MB_BITSTRM_FLOW_ERR rw — Underflow/overflow in bitstream during MB decode/encode error interrupt enable.
  [7] SCS_ON_EOS_BITSTRM_UNDERFLOW_ERR rw — Underflow in bitstream during startcode search after EOS error interrupt enable.
  [5] UP_SCS_BITSTRM_UNDERFLOW_ERR rw — Underflow in bitstream during startcode search unit processing.
  [4] BITSTREAM_UNINIT_ERR rw — Bitstream initialization without bitstream descriptor programmation error interrupt enable
  [2] FE_DETECTED_ERR rw — BE error due to error detected in FE interrupt enable.
  [1] TEMPORAL_B_DIRECT_ERR rw — Temporal B Direct Detected Error Interrupt Enable
  [0] CAVLC_DEC_ERR rw — CAVLC Decoder Error Interrupt Enable
